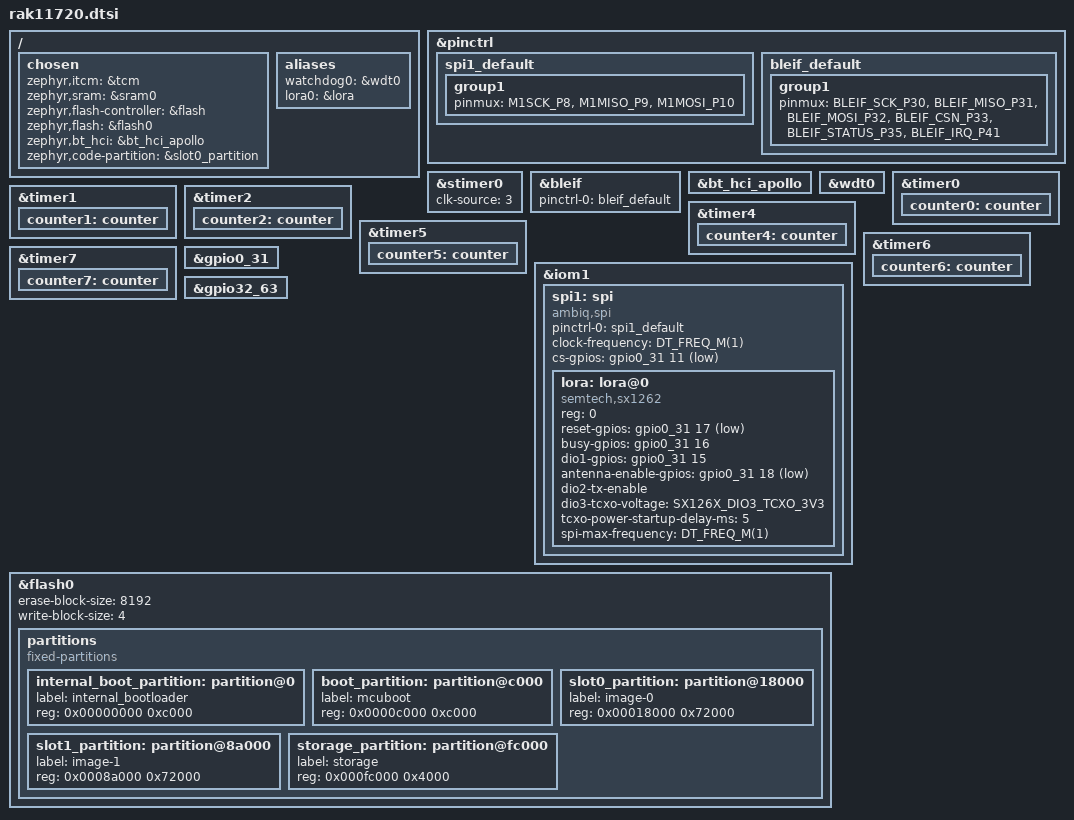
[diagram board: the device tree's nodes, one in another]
/*
 * SPDX-License-Identifier: Apache-2.0
 * Copyright (c) 2026 RAKwireless Technology Limited
 *
 * RAK11720 pinout description
 * https://docs.rakwireless.com/product-categories/wisduo/rak11720-module/datasheet
 *
 * P1 	- GP43/UART1_RX
 * P2 	- GP42/UART1_TX
 * P3 	- GP12/ADC9
 * P4 	- GP39/UART0_TX
 * P5 	- GP40/UART0_RX
 * P6 	- GP45
 * P7 	- GP21/SWDIO
 * P8 	- GP20/SWDCK
 * P9 	- GP27/I2C2_SCL
 * P10	- GP25/I2C2_SDA
 * P11	- GND
 * P12	- LORA_RF
 *
 * P13	- GP7/SPI0_MOSI
 * P14	- GP6/SPI0_MISO
 * P15	- GP5/SPI0_SCK
 * P16	- GP1/SPI0_NSS
 *
 * P17	- GND
 * P18	- GND
 * P19	- GP4 - IO2
 * P20	- GP36 - IO6
 * P21	- SWO
 * P22	- RST
 * P23	- GND
 * P24	- VDD
 *
 * P25	- GP32/ADC4 - IO7
 * P26	- GP31/ADC3
 * P27	- GP37
 * P28	- GND
 * P29	- GP44
 * P30	- GP38
 * P31	- GP33/ADC5
 * P32	- GP13/ADC8
 * P33	- BLE_RF
 * P34	- GND
 */

#include <ambiq/ambiq_apollo3_blue.dtsi>
#include <zephyr/dt-bindings/pinctrl/ambiq-apollo3-pinctrl.h>
#include <zephyr/dt-bindings/lora/sx126x.h>

&pinctrl {
	spi1_default: spi1_default {
		group1 {
			pinmux = <M1SCK_P8>, <M1MISO_P9>, <M1MOSI_P10>;
		};
	};

	bleif_default: bleif_default {
		group1 {
			pinmux = <BLEIF_SCK_P30>,
				 <BLEIF_MISO_P31>,
				 <BLEIF_MOSI_P32>,
				 <BLEIF_CSN_P33>,
				 <BLEIF_STATUS_P35>,
				 <BLEIF_IRQ_P41>;
		};
	};
};

/ {
	chosen {
		zephyr,itcm = &tcm;
		zephyr,sram = &sram0;
		zephyr,flash-controller = &flash;
		zephyr,flash = &flash0;
		zephyr,bt_hci = &bt_hci_apollo;
		zephyr,code-partition = &slot0_partition;
	};

	aliases {
		watchdog0 = &wdt0;
		lora0 = &lora;
	};
};

&stimer0 {
	clk-source = <3>;
};

&bleif {
	status = "okay";
	pinctrl-0 = <&bleif_default>;
	pinctrl-names = "default";
};

&bt_hci_apollo {
	status = "okay";
};

&wdt0 {
	status = "okay";
};

&timer0 {
	counter0: counter {
		status = "okay";
	};
};

&timer1 {
	counter1: counter {
		status = "okay";
	};
};

&timer2 {
	counter2: counter {
		status = "okay";
	};
};

&timer4 {
	counter4: counter {
		status = "okay";
	};
};

&timer5 {
	counter5: counter {
		status = "okay";
	};
};

&timer6 {
	counter6: counter {
		status = "okay";
	};
};

&timer7 {
	counter7: counter {
		status = "okay";
	};
};

&iom1 {
	spi1: spi {
		compatible = "ambiq,spi";
		status = "okay";
		pinctrl-0 = <&spi1_default>;
		pinctrl-names = "default";
		clock-frequency = <DT_FREQ_M(1)>;
		cs-gpios = <&gpio0_31 11 GPIO_ACTIVE_LOW>;

		lora: lora@0 {
			compatible = "semtech,sx1262";
			reg = <0>;
			reset-gpios = <&gpio0_31 17 GPIO_ACTIVE_LOW>;
			busy-gpios = <&gpio0_31 16 GPIO_ACTIVE_HIGH>;
			dio1-gpios = <&gpio0_31 15 GPIO_ACTIVE_HIGH>;
			antenna-enable-gpios = <&gpio0_31 18 GPIO_ACTIVE_LOW>;
			dio2-tx-enable;
			dio3-tcxo-voltage = <SX126X_DIO3_TCXO_3V3>;
			tcxo-power-startup-delay-ms = <5>;
			spi-max-frequency = <DT_FREQ_M(1)>;
		};
	};
};


&gpio0_31 {
	status = "okay";
};

&gpio32_63 {
	status = "okay";
};
&flash0 {
	erase-block-size = <8192>;
	write-block-size = <4>;

	partitions {
		compatible = "fixed-partitions";
		#address-cells = <1>;
		#size-cells = <1>;

		internal_boot_partition: partition@0 {
			label = "internal_bootloader";
			reg = <0x00000000 0xc000>;
		};

		boot_partition: partition@c000 {
			label = "mcuboot";
			reg = <0x0000c000 0xc000>;
		};

		slot0_partition: partition@18000 {
			label = "image-0";
			reg = <0x00018000 0x72000>;
		};

		slot1_partition: partition@8a000 {
			label = "image-1";
			reg = <0x0008a000 0x72000>;
		};

		storage_partition: partition@fc000 {
			label = "storage";
			reg = <0x000fc000 0x4000>;
		};
	};
};

